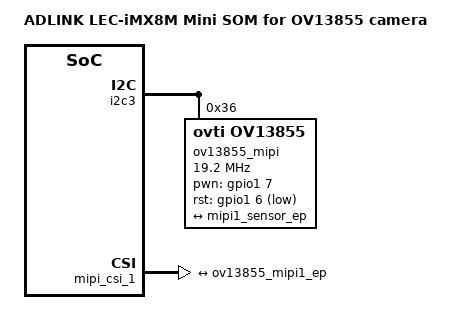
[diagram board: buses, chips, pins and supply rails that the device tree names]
/*
 *
 */


#include "lec-imx8mm.dts"

/{
	model = "ADLINK LEC-iMX8M Mini SOM for OV13855 camera";
};


&i2c3 {

	/delete-node/ ov5640_mipi@3c;
	
	ov13855_mipi: ov13855_mipi@36 {
        compatible = "ovti,ov13855";
        reg = <0x36>;
        pinctrl-names = "okay";
        pinctrl-0 = <&pinctrl_csi_pwn>, <&pinctrl_csi_rst>;
        clocks = <&clk IMX8MM_CLK_CLKO1>;
        clock-names = "csi_mclk";
        clock-frequency = <19200000>;
        rotation = <0>;
        assigned-clocks = <&clk IMX8MM_CLK_CLKO1>;
        assigned-clock-parents = <&clk IMX8MM_CLK_24M>;
        assigned-clock-rates = <24000000>;
        csi_id = <0>;
        pwn-gpios = <&gpio1 7 GPIO_ACTIVE_HIGH>;
        rst-gpios = <&gpio1 6 GPIO_ACTIVE_LOW>;
        virtual_channel = <0>;
        mclk = <24000000>;
        mclk_source = <0>;
        mipi_csi;
        status = "okay";

        port {
                ov13855_mipi1_ep: endpoint {
                        remote-endpoint = <&mipi1_sensor_ep>;
                        data-lanes = <4>;
                        //clock-lanes = <0>;
                        csis-hs-settle = <13>;
                        csis-cls-settle = <2>;
                        link-frequencies = /bits/64<297000000>;
                };
        };
    };
};

&mipi_csi_1 {
	/delete-node/ endpoint@1;
	port {
		mipi1_sensor_ep: endpoint@1 {
			remote-endpoint = <&ov13855_mipi1_ep>;
			data-lanes = <4>;
			csis-hs-settle = <13>;
			csis-clk-settle = <2>;
			csis-wclk;
			link-frequencies = /bits/64<297000000>;
		};
	};
};

